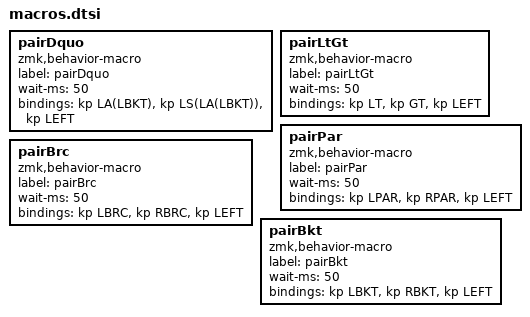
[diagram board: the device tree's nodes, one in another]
pairDquo: pairDquo {
        label = "pairDquo";
        compatible = "zmk,behavior-macro";
        #binding-cells = <0>;
        wait-ms = <50>; // need to slow this down for some systems.
        bindings = <&kp LA(LBKT) &kp LS(LA(LBKT)) &kp LEFT>;
};
pairLtGt: pairLtGt {
        label = "pairLtGt";
        compatible = "zmk,behavior-macro";
        #binding-cells = <0>;
        wait-ms = <50>; // need to slow this down for some systems.
        bindings = <&kp LT &kp GT &kp LEFT>;
};
pairPar: pairPar {
        label = "pairPar";
        compatible = "zmk,behavior-macro";
        #binding-cells = <0>;
        wait-ms = <50>; // need to slow this down for some systems.
        bindings = <&kp LPAR &kp RPAR &kp LEFT>;
};
pairBrc: pairBrc {
        label = "pairBrc";
        compatible = "zmk,behavior-macro";
        #binding-cells = <0>;
        wait-ms = <50>; // need to slow this down for some systems.
        bindings = <&kp LBRC &kp RBRC &kp LEFT>;
};
pairBkt: pairBkt {
        label = "pairBkt";
        compatible = "zmk,behavior-macro";
        #binding-cells = <0>;
        wait-ms = <50>; // need to slow this down for some systems.
        bindings = <&kp LBKT &kp RBKT &kp LEFT>;
};
